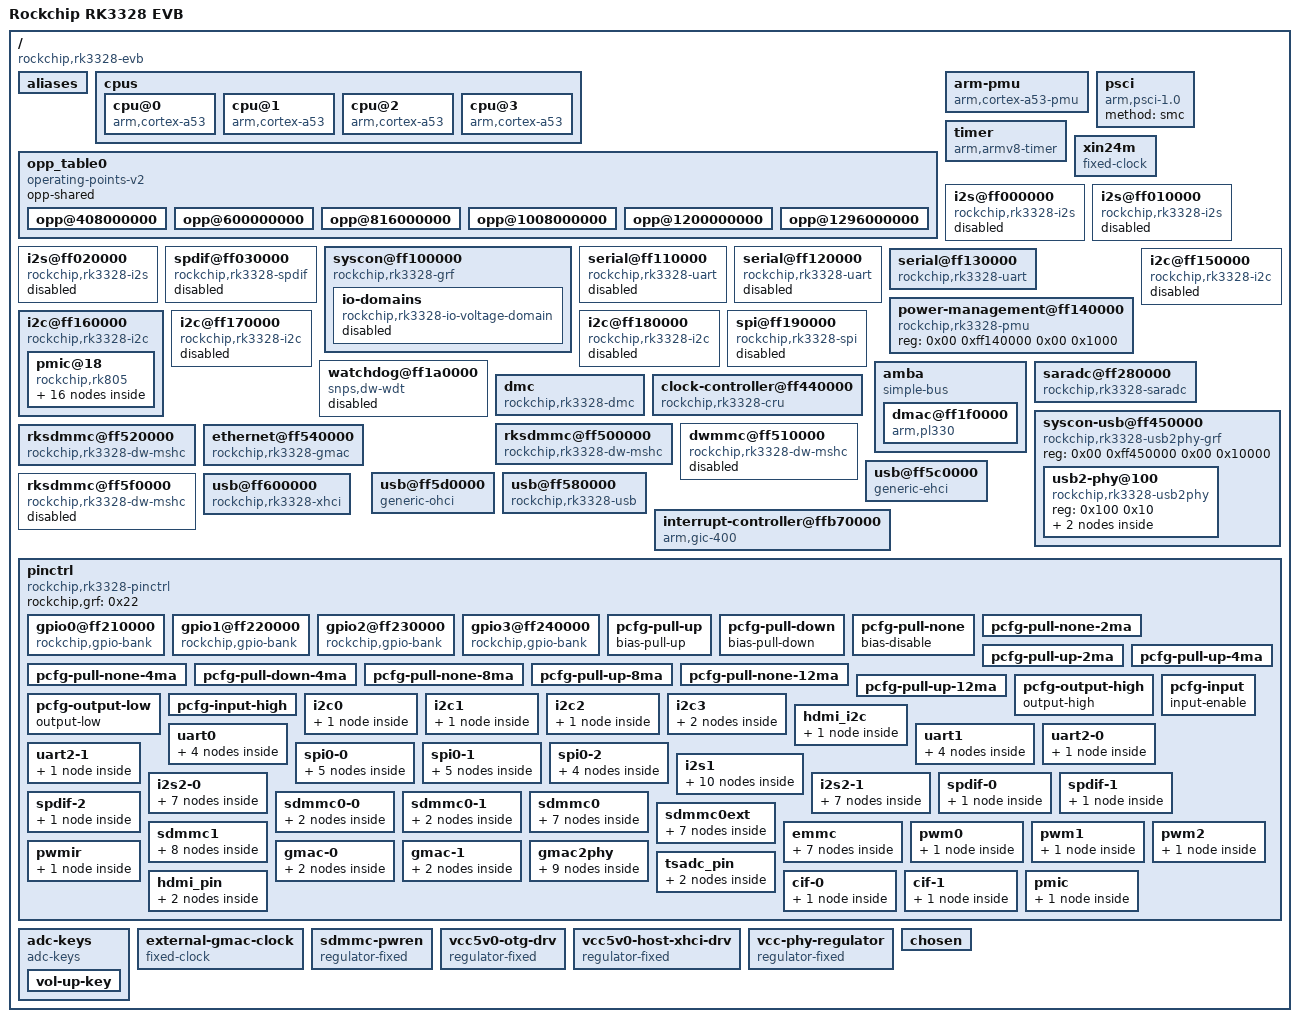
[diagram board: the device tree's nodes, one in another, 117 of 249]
/dts-v1/;

/ {
	compatible = "rockchip,rk3328-evb\0rockchip,rk3328";
	interrupt-parent = <0x01>;
	#address-cells = <0x02>;
	#size-cells = <0x02>;
	model = "Rockchip RK3328 EVB";

	aliases {
		serial0 = "/serial@ff110000";
		serial1 = "/serial@ff120000";
		serial2 = "/serial@ff130000";
		i2c0 = "/i2c@ff150000";
		i2c1 = "/i2c@ff160000";
		i2c2 = "/i2c@ff170000";
		i2c3 = "/i2c@ff180000";
		mmc0 = "/rksdmmc@ff520000";
		mmc1 = "/rksdmmc@ff500000";
		mmc2 = "/rksdmmc@ff5f0000";
	};

	cpus {
		#address-cells = <0x02>;
		#size-cells = <0x00>;

		cpu@0 {
			device_type = "cpu";
			compatible = "arm,cortex-a53\0arm,armv8";
			reg = <0x00 0x00>;
			enable-method = "psci";
			operating-points-v2 = <0x02>;
			phandle = <0x03>;
		};

		cpu@1 {
			device_type = "cpu";
			compatible = "arm,cortex-a53\0arm,armv8";
			reg = <0x00 0x01>;
			enable-method = "psci";
			phandle = <0x04>;
		};

		cpu@2 {
			device_type = "cpu";
			compatible = "arm,cortex-a53\0arm,armv8";
			reg = <0x00 0x02>;
			enable-method = "psci";
			phandle = <0x05>;
		};

		cpu@3 {
			device_type = "cpu";
			compatible = "arm,cortex-a53\0arm,armv8";
			reg = <0x00 0x03>;
			enable-method = "psci";
			phandle = <0x06>;
		};
	};

	opp_table0 {
		compatible = "operating-points-v2";
		opp-shared;
		phandle = <0x02>;

		opp@408000000 {
			opp-hz = <0x00 0x18519600>;
			opp-microvolt = <0xe7ef0>;
			clock-latency-ns = <0x9c40>;
			opp-suspend;
		};

		opp@600000000 {
			opp-hz = <0x00 0x23c34600>;
			opp-microvolt = <0xe7ef0>;
			clock-latency-ns = <0x9c40>;
		};

		opp@816000000 {
			opp-hz = <0x00 0x30a32c00>;
			opp-microvolt = <0xf4240>;
			clock-latency-ns = <0x9c40>;
		};

		opp@1008000000 {
			opp-hz = <0x00 0x3c14dc00>;
			opp-microvolt = <0x10c8e0>;
			clock-latency-ns = <0x9c40>;
		};

		opp@1200000000 {
			opp-hz = <0x00 0x47868c00>;
			opp-microvolt = <0x12b128>;
			clock-latency-ns = <0x9c40>;
		};

		opp@1296000000 {
			opp-hz = <0x00 0x4d3f6400>;
			opp-microvolt = <0x13d620>;
			clock-latency-ns = <0x9c40>;
		};
	};

	arm-pmu {
		compatible = "arm,cortex-a53-pmu";
		interrupts = <0x00 0x64 0x04 0x00 0x65 0x04 0x00 0x66 0x04 0x00 0x67 0x04>;
		interrupt-affinity = <0x03 0x04 0x05 0x06>;
	};

	psci {
		compatible = "arm,psci-1.0";
		method = "smc";
	};

	timer {
		compatible = "arm,armv8-timer";
		interrupts = <0x01 0x0d 0xf08 0x01 0x0e 0xf08 0x01 0x0b 0xf08 0x01 0x0a 0xf08>;
	};

	xin24m {
		compatible = "fixed-clock";
		#clock-cells = <0x00>;
		clock-frequency = <0x16e3600>;
		clock-output-names = "xin24m";
		phandle = <0x23>;
	};

	i2s@ff000000 {
		compatible = "rockchip,rk3328-i2s\0rockchip,rk3066-i2s";
		reg = <0x00 0xff000000 0x00 0x1000>;
		interrupts = <0x00 0x1a 0x04>;
		clocks = <0x07 0x29 0x07 0x137>;
		clock-names = "i2s_clk\0i2s_hclk";
		dmas = <0x08 0x0b 0x08 0x0c>;
		#dma-cells = <0x02>;
		dma-names = "tx\0rx";
		status = "disabled";
	};

	i2s@ff010000 {
		compatible = "rockchip,rk3328-i2s\0rockchip,rk3066-i2s";
		reg = <0x00 0xff010000 0x00 0x1000>;
		interrupts = <0x00 0x1b 0x04>;
		clocks = <0x07 0x2a 0x07 0x138>;
		clock-names = "i2s_clk\0i2s_hclk";
		dmas = <0x08 0x0e 0x08 0x0f>;
		#dma-cells = <0x02>;
		dma-names = "tx\0rx";
		status = "disabled";
	};

	i2s@ff020000 {
		compatible = "rockchip,rk3328-i2s\0rockchip,rk3066-i2s";
		reg = <0x00 0xff020000 0x00 0x1000>;
		interrupts = <0x00 0x1c 0x04>;
		clocks = <0x07 0x2b 0x07 0x139>;
		clock-names = "i2s_clk\0i2s_hclk";
		dmas = <0x08 0x00 0x08 0x01>;
		#dma-cells = <0x02>;
		dma-names = "tx\0rx";
		pinctrl-names = "default\0sleep";
		pinctrl-0 = <0x09 0x0a 0x0b 0x0c 0x0d 0x0e>;
		pinctrl-1 = <0x0f>;
		status = "disabled";
	};

	spdif@ff030000 {
		compatible = "rockchip,rk3328-spdif";
		reg = <0x00 0xff030000 0x00 0x1000>;
		interrupts = <0x00 0x1d 0x04>;
		clocks = <0x07 0x2e 0x07 0x13a>;
		clock-names = "mclk\0hclk";
		dmas = <0x08 0x0a>;
		#dma-cells = <0x01>;
		dma-names = "tx";
		pinctrl-names = "default";
		pinctrl-0 = <0x10>;
		status = "disabled";
	};

	syscon@ff100000 {
		compatible = "rockchip,rk3328-grf\0syscon\0simple-mfd";
		reg = <0x00 0xff100000 0x00 0x1000>;
		#address-cells = <0x01>;
		#size-cells = <0x01>;
		u-boot,dm-pre-reloc;
		phandle = <0x22>;

		io-domains {
			compatible = "rockchip,rk3328-io-voltage-domain";
			status = "disabled";
		};
	};

	serial@ff110000 {
		compatible = "rockchip,rk3328-uart\0snps,dw-apb-uart";
		reg = <0x00 0xff110000 0x00 0x100>;
		interrupts = <0x00 0x37 0x04>;
		clocks = <0x07 0x26 0x07 0xd2>;
		clock-names = "baudclk\0apb_pclk";
		reg-shift = <0x02>;
		reg-io-width = <0x04>;
		dmas = <0x08 0x02 0x08 0x03>;
		#dma-cells = <0x02>;
		pinctrl-names = "default";
		pinctrl-0 = <0x11 0x12 0x13>;
		status = "disabled";
	};

	serial@ff120000 {
		compatible = "rockchip,rk3328-uart\0snps,dw-apb-uart";
		reg = <0x00 0xff120000 0x00 0x100>;
		interrupts = <0x00 0x38 0x04>;
		clocks = <0x07 0x27 0x07 0xd3>;
		clock-names = "sclk_uart\0pclk_uart";
		reg-shift = <0x02>;
		reg-io-width = <0x04>;
		dmas = <0x08 0x04 0x08 0x05>;
		#dma-cells = <0x02>;
		pinctrl-names = "default";
		pinctrl-0 = <0x14 0x15 0x16>;
		status = "disabled";
	};

	serial@ff130000 {
		compatible = "rockchip,rk3328-uart\0snps,dw-apb-uart";
		reg = <0x00 0xff130000 0x00 0x100>;
		interrupts = <0x00 0x39 0x04>;
		clocks = <0x07 0x28 0x07 0xd4>;
		clock-names = "baudclk\0apb_pclk";
		clock-frequency = <0x16e3600>;
		reg-shift = <0x02>;
		reg-io-width = <0x04>;
		dmas = <0x08 0x06 0x08 0x07>;
		#dma-cells = <0x02>;
		pinctrl-names = "default";
		pinctrl-0 = <0x17>;
		status = "okay";
		u-boot,dm-pre-reloc;
	};

	power-management@ff140000 {
		compatible = "rockchip,rk3328-pmu\0syscon\0simple-mfd";
		reg = <0x00 0xff140000 0x00 0x1000>;
	};

	i2c@ff150000 {
		compatible = "rockchip,rk3328-i2c";
		reg = <0x00 0xff150000 0x00 0x1000>;
		interrupts = <0x00 0x24 0x04>;
		#address-cells = <0x01>;
		#size-cells = <0x00>;
		clocks = <0x07 0x37 0x07 0xcd>;
		clock-names = "i2c\0pclk";
		pinctrl-names = "default";
		pinctrl-0 = <0x18>;
		status = "disabled";
	};

	i2c@ff160000 {
		compatible = "rockchip,rk3328-i2c";
		reg = <0x00 0xff160000 0x00 0x1000>;
		interrupts = <0x00 0x25 0x04>;
		#address-cells = <0x01>;
		#size-cells = <0x00>;
		clocks = <0x07 0x38 0x07 0xce>;
		clock-names = "i2c\0pclk";
		pinctrl-names = "default";
		pinctrl-0 = <0x19>;
		status = "okay";
		clock-frequency = <0x61a80>;
		i2c-scl-rising-time-ns = <0xa8>;
		i2c-scl-falling-time-ns = <0x04>;

		pmic@18 {
			compatible = "rockchip,rk805";
			status = "okay";
			reg = <0x18>;
			interrupt-parent = <0x1a>;
			interrupts = <0x06 0x08>;
			pinctrl-names = "default";
			pinctrl-0 = <0x1b>;
			rockchip,system-power-controller;
			wakeup-source;
			gpio-controller;
			#gpio-cells = <0x02>;
			#clock-cells = <0x01>;
			clock-output-names = "xin32k\0rk805-clkout2";

			pwrkey {
				status = "okay";
			};

			regulators {

				DCDC_REG1 {
					regulator-name = "vdd_logic";
					regulator-min-microvolt = <0xadf34>;
					regulator-max-microvolt = <0x162010>;
					regulator-ramp-delay = <0x1771>;
					regulator-boot-on;
					regulator-always-on;

					regulator-state-mem {
						regulator-on-in-suspend;
						regulator-suspend-microvolt = <0xf4240>;
					};
				};

				DCDC_REG2 {
					regulator-name = "vdd_arm";
					regulator-min-microvolt = <0xadf34>;
					regulator-max-microvolt = <0x162010>;
					regulator-ramp-delay = <0x1771>;
					regulator-boot-on;
					regulator-always-on;

					regulator-state-mem {
						regulator-on-in-suspend;
						regulator-suspend-microvolt = <0xf4240>;
					};
				};

				DCDC_REG3 {
					regulator-name = "vcc_ddr";
					regulator-boot-on;
					regulator-always-on;

					regulator-state-mem {
						regulator-on-in-suspend;
					};
				};

				DCDC_REG4 {
					regulator-name = "vcc_io";
					regulator-min-microvolt = <0x325aa0>;
					regulator-max-microvolt = <0x325aa0>;
					regulator-boot-on;
					regulator-always-on;

					regulator-state-mem {
						regulator-on-in-suspend;
						regulator-suspend-microvolt = <0x325aa0>;
					};
				};

				LDO_REG1 {
					regulator-name = "vdd_18";
					regulator-min-microvolt = <0x1b7740>;
					regulator-max-microvolt = <0x1b7740>;
					regulator-boot-on;
					regulator-always-on;

					regulator-state-mem {
						regulator-on-in-suspend;
						regulator-suspend-microvolt = <0x1b7740>;
					};
				};

				LDO_REG2 {
					regulator-name = "vcc_18emmc";
					regulator-min-microvolt = <0x1b7740>;
					regulator-max-microvolt = <0x1b7740>;
					regulator-boot-on;
					regulator-always-on;

					regulator-state-mem {
						regulator-on-in-suspend;
						regulator-suspend-microvolt = <0x1b7740>;
					};
				};

				LDO_REG3 {
					regulator-name = "vdd_10";
					regulator-min-microvolt = <0xf4240>;
					regulator-max-microvolt = <0xf4240>;
					regulator-boot-on;
					regulator-always-on;

					regulator-state-mem {
						regulator-on-in-suspend;
						regulator-suspend-microvolt = <0xf4240>;
					};
				};
			};
		};
	};

	i2c@ff170000 {
		compatible = "rockchip,rk3328-i2c";
		reg = <0x00 0xff170000 0x00 0x1000>;
		interrupts = <0x00 0x26 0x04>;
		#address-cells = <0x01>;
		#size-cells = <0x00>;
		clocks = <0x07 0x39 0x07 0xcf>;
		clock-names = "i2c\0pclk";
		pinctrl-names = "default";
		pinctrl-0 = <0x1c>;
		status = "disabled";
	};

	i2c@ff180000 {
		compatible = "rockchip,rk3328-i2c";
		reg = <0x00 0xff180000 0x00 0x1000>;
		interrupts = <0x00 0x27 0x04>;
		#address-cells = <0x01>;
		#size-cells = <0x00>;
		clocks = <0x07 0x3a 0x07 0xd0>;
		clock-names = "i2c\0pclk";
		pinctrl-names = "default";
		pinctrl-0 = <0x1d>;
		status = "disabled";
	};

	spi@ff190000 {
		compatible = "rockchip,rk3328-spi\0rockchip,rk3066-spi";
		reg = <0x00 0xff190000 0x00 0x1000>;
		interrupts = <0x00 0x31 0x04>;
		#address-cells = <0x01>;
		#size-cells = <0x00>;
		clocks = <0x07 0x20 0x07 0xd1>;
		clock-names = "spiclk\0apb_pclk";
		dmas = <0x08 0x08 0x08 0x09>;
		#dma-cells = <0x02>;
		dma-names = "tx\0rx";
		pinctrl-names = "default";
		pinctrl-0 = <0x1e 0x1f 0x20 0x21>;
		status = "disabled";
	};

	watchdog@ff1a0000 {
		compatible = "snps,dw-wdt";
		reg = <0x00 0xff1a0000 0x00 0x100>;
		interrupts = <0x00 0x28 0x04>;
		status = "disabled";
	};

	amba {
		compatible = "simple-bus";
		#address-cells = <0x02>;
		#size-cells = <0x02>;
		ranges;

		dmac@ff1f0000 {
			compatible = "arm,pl330\0arm,primecell";
			reg = <0x00 0xff1f0000 0x00 0x4000>;
			interrupts = <0x00 0x00 0x04 0x00 0x01 0x04>;
			clocks = <0x07 0x86>;
			clock-names = "apb_pclk";
			#dma-cells = <0x01>;
			phandle = <0x08>;
		};
	};

	saradc@ff280000 {
		compatible = "rockchip,rk3328-saradc\0rockchip,saradc";
		reg = <0x00 0xff280000 0x00 0x100>;
		interrupts = <0x00 0x50 0x04>;
		#io-channel-cells = <0x01>;
		clocks = <0x07 0x25 0x07 0xea>;
		clock-names = "saradc\0apb_pclk";
		resets = <0x07 0x56>;
		reset-names = "saradc-apb";
		status = "okay";
		u-boot,dm-spl;
		phandle = <0x3f>;
	};

	dmc {
		compatible = "rockchip,rk3328-dmc";
		reg = <0x00 0xff400000 0x00 0x1000 0x00 0xff780000 0x00 0x3000 0x00 0xff100000 0x00 0x1000 0x00 0xff440000 0x00 0x1000 0x00 0xff720000 0x00 0x1000 0x00 0xff798000 0x00 0x1000>;
		rockchip,sdram-params = <0x01 0x0c 0x03 0x01 0x00 0x00 0x10 0x10 0x10 0x10 0x00 0x9028b189 0x00 0x21 0x482 0x15 0x222 0xff 0x14d 0x03 0x01 0x00 0x00 0x00 0x43041001 0x64 0x28003b 0xd0 0x20053 0xd4 0x20000 0xd8 0x100 0xdc 0x3200000 0xe0 0x00 0xe4 0x90000 0xf4 0xf011f 0x100 0x7090b06 0x104 0x50209 0x108 0x3030407 0x10c 0x202006 0x110 0x3020204 0x114 0x3030202 0x120 0x903 0x180 0x800020 0x184 0x00 0x190 0x7010001 0x198 0x5001100 0x1a0 0xc0400003 0x240 0x6000604 0x244 0x201 0x250 0xf00 0x490 0x01 0xffffffff 0xffffffff 0xffffffff 0xffffffff 0xffffffff 0xffffffff 0xffffffff 0xffffffff 0xffffffff 0xffffffff 0x04 0x0a 0x28 0x06 0x2c 0x00 0x30 0x05 0xffffffff 0xffffffff 0x77 0x88 0x79 0x79 0x87 0x97 0x87 0x78 0x77 0x78 0x87 0x88 0x87 0x87 0x77 0x78 0x78 0x78 0x78 0x78 0x78 0x78 0x78 0x78 0x69 0x09 0x77 0x78 0x77 0x78 0x77 0x78 0x77 0x78 0x77 0x79 0x09 0x78 0x78 0x78 0x78 0x78 0x78 0x78 0x78 0x78 0x69 0x09 0x77 0x78 0x77 0x77 0x77 0x77 0x77 0x77 0x77 0x79 0x09 0x78 0x78 0x78 0x78 0x78 0x78 0x78 0x78 0x78 0x69 0x09 0x77 0x78 0x77 0x78 0x77 0x78 0x77 0x78 0x77 0x79 0x09 0x78 0x78 0x78 0x78 0x78 0x78 0x78 0x78 0x78 0x69 0x09 0x77 0x78 0x77 0x77 0x77 0x77 0x77 0x77 0x77 0x79 0x09>;
		u-boot,dm-pre-reloc;
	};

	clock-controller@ff440000 {
		compatible = "rockchip,rk3328-cru\0rockchip,cru\0syscon";
		reg = <0x00 0xff440000 0x00 0x1000>;
		rockchip,grf = <0x22>;
		#clock-cells = <0x01>;
		#reset-cells = <0x01>;
		assigned-clocks = <0x07 0x78 0x07 0x3d 0x07 0x1e 0x07 0x26 0x07 0x27 0x07 0x28 0x07 0x88 0x07 0x89 0x07 0x8e 0x07 0x85 0x07 0x83 0x07 0x8a 0x07 0x8c 0x07 0x8d 0x07 0x41 0x07 0x42 0x07 0x44 0x07 0x43 0x07 0x22 0x07 0x5c 0x07 0x35 0x07 0x06 0x07 0x04 0x07 0x03 0x07 0x88 0x07 0x148 0x07 0xd8 0x07 0x89 0x07 0x134 0x07 0xe6 0x07 0x8e 0x07 0x145 0x07 0x85 0x07 0x45 0x07 0x83 0x07 0x8a 0x07 0x8c 0x07 0x8d 0x07 0x41 0x07 0x42 0x07 0x44 0x07 0x43 0x07 0x3e 0x07 0xe5 0x07 0x92 0x07 0xdc 0x07 0x1e 0x07 0x61>;
		assigned-clock-parents = <0x07 0x7a 0x07 0x01 0x07 0x04 0x23 0x23 0x23>;
		assigned-clock-rates = <0x00 0x3a98000 0x00 0x16e3600 0x16e3600 0x16e3600 0x8f0d180 0x8f0d180 0x5f5e100 0x5f5e100 0x5f5e100 0x5f5e100 0x2faf080 0x5f5e100 0x5f5e100 0x5f5e100 0x2faf080 0x2faf080 0x2faf080 0x2faf080 0x16e3600 0x23c34600 0x1d4c0000 0x47868c00 0x8f0d180 0x47868c0 0x47868c0 0x8f0d180 0x47868c0 0x47868c0 0x11e1a300 0x5f5e100 0x11e1a300 0xbebc200 0x17d78400 0x1dcd6500 0xbebc200 0x11e1a300 0x11e1a300 0xee6b280 0xbebc200 0x5f5e100 0x16e3600 0x5f5e100 0x8f0d180 0x2faf080 0x8000 0x8000>;
		u-boot,dm-pre-reloc;
		phandle = <0x07>;
	};

	syscon-usb@ff450000 {
		compatible = "rockchip,rk3328-usb2phy-grf\0simple-mfd\0syscon";
		reg = <0x00 0xff450000 0x00 0x10000>;
		#address-cells = <0x01>;
		#size-cells = <0x01>;
		u-boot,dm-spl;

		usb2-phy@100 {
			compatible = "rockchip,rk3328-usb2phy";
			reg = <0x100 0x10>;
			#phy-cells = <0x01>;
			status = "okay";
			u-boot,dm-spl;

			otg-port {
				#phy-cells = <0x00>;
				interrupts = <0x00 0x3b 0x04 0x00 0x3c 0x04 0x00 0x3d 0x04>;
				interrupt-names = "otg-bvalid\0otg-id\0linestate";
				status = "okay";
				u-boot,dm-spl;
				phandle = <0x32>;
			};

			host-port {
				#phy-cells = <0x00>;
				interrupts = <0x00 0x3e 0x04>;
				interrupt-names = "linestate";
				status = "okay";
				u-boot,dm-spl;
				phandle = <0x30>;
			};
		};
	};

	rksdmmc@ff500000 {
		compatible = "rockchip,rk3328-dw-mshc\0rockchip,rk3288-dw-mshc";
		reg = <0x00 0xff500000 0x00 0x4000>;
		max-frequency = <0x8f0d180>;
		clocks = <0x07 0x13d 0x07 0x21 0x07 0x4a 0x07 0x4e>;
		clock-names = "biu\0ciu\0ciu-drv\0ciu-sample";
		fifo-depth = <0x100>;
		interrupts = <0x00 0x0c 0x04>;
		status = "okay";
		bus-width = <0x04>;
		cap-mmc-highspeed;
		cap-sd-highspeed;
		card-detect-delay = <0xc8>;
		disable-wp;
		num-slots = <0x01>;
		pinctrl-names = "default";
		pinctrl-0 = <0x24 0x25 0x26 0x27>;
		vmmc-supply = <0x28>;
		u-boot,dm-spl;
	};

	dwmmc@ff510000 {
		compatible = "rockchip,rk3328-dw-mshc\0rockchip,rk3288-dw-mshc";
		reg = <0x00 0xff510000 0x00 0x4000>;
		max-frequency = <0x8f0d180>;
		clocks = <0x07 0x13e 0x07 0x22 0x07 0x4b 0x07 0x4f>;
		clock-names = "biu\0ciu\0ciu-drv\0ciu-sample";
		fifo-depth = <0x100>;
		interrupts = <0x00 0x0d 0x04>;
		status = "disabled";
	};

	rksdmmc@ff520000 {
		compatible = "rockchip,rk3328-dw-mshc\0rockchip,rk3288-dw-mshc";
		reg = <0x00 0xff520000 0x00 0x4000>;
		max-frequency = <0x8f0d180>;
		clocks = <0x07 0x13f 0x07 0x23 0x07 0x4c 0x07 0x50>;
		clock-names = "biu\0ciu\0ciu-drv\0ciu-sample";
		fifo-depth = <0x100>;
		interrupts = <0x00 0x0e 0x04>;
		status = "okay";
		bus-width = <0x08>;
		cap-mmc-highspeed;
		supports-emmc;
		disable-wp;
		non-removable;
		num-slots = <0x01>;
		pinctrl-names = "default";
		pinctrl-0 = <0x29 0x2a 0x2b>;
		u-boot,dm-spl;
	};

	ethernet@ff540000 {
		compatible = "rockchip,rk3328-gmac";
		reg = <0x00 0xff540000 0x00 0x10000>;
		rockchip,grf = <0x22>;
		interrupts = <0x00 0x18 0x04>;
		interrupt-names = "macirq";
		clocks = <0x07 0x64 0x07 0x57 0x07 0x58 0x07 0x5a 0x07 0x59 0x07 0x96 0x07 0xdf>;
		clock-names = "stmmaceth\0mac_clk_rx\0mac_clk_tx\0clk_mac_ref\0clk_mac_refout\0aclk_mac\0pclk_mac";
		resets = <0x07 0x63>;
		reset-names = "stmmaceth";
		status = "okay";
		phy-supply = <0x2c>;
		phy-mode = "rgmii";
		clock_in_out = "input";
		snps,reset-gpio = <0x2d 0x12 0x01>;
		snps,reset-active-low;
		snps,reset-delays-us = <0x00 0x2710 0xc350>;
		assigned-clocks = <0x07 0x64 0x07 0x66>;
		assigned-clock-parents = <0x2e 0x2e>;
		pinctrl-names = "default";
		pinctrl-0 = <0x2f>;
		tx_delay = <0x26>;
		rx_delay = <0x11>;
	};

	usb@ff5c0000 {
		compatible = "generic-ehci";
		reg = <0x00 0xff5c0000 0x00 0x10000>;
		interrupts = <0x00 0x10 0x04>;
		phys = <0x30>;
		phy-names = "usb";
		status = "okay";
		vbus-supply = <0x31>;
		u-boot,dm-spl;
	};

	usb@ff5d0000 {
		compatible = "generic-ohci";
		reg = <0x00 0xff5d0000 0x00 0x10000>;
		interrupts = <0x00 0x11 0x04>;
		phys = <0x30>;
		phy-names = "usb";
		status = "okay";
	};

	usb@ff580000 {
		compatible = "rockchip,rk3328-usb\0rockchip,rk3066-usb\0snps,dwc2";
		reg = <0x00 0xff580000 0x00 0x40000>;
		interrupts = <0x00 0x17 0x04>;
		hnp-srp-disable;
		dr_mode = "otg";
		phys = <0x32>;
		phy-names = "usb";
		status = "okay";
		vbus-supply = <0x31>;
		u-boot,dm-spl;
	};

	rksdmmc@ff5f0000 {
		compatible = "rockchip,rk3328-dw-mshc\0rockchip,rk3288-dw-mshc";
		reg = <0x00 0xff5f0000 0x00 0x4000>;
		max-frequency = <0x8f0d180>;
		clocks = <0x07 0x13d 0x07 0x21>;
		clock-names = "biu\0ciu";
		fifo-depth = <0x100>;
		interrupts = <0x00 0x04 0x04>;
		status = "disabled";
	};

	usb@ff600000 {
		compatible = "rockchip,rk3328-xhci";
		reg = <0x00 0xff600000 0x00 0x100000>;
		interrupts = <0x00 0x43 0x04>;
		snps,dis-enblslpm-quirk;
		snps,phyif-utmi-bits = <0x10>;
		snps,dis-u2-freeclk-exists-quirk;
		snps,dis-u2-susphy-quirk;
		status = "okay";
		vbus-supply = <0x33>;
		u-boot,dm-spl;
	};

	interrupt-controller@ffb70000 {
		compatible = "arm,gic-400";
		#interrupt-cells = <0x03>;
		#address-cells = <0x00>;
		interrupt-controller;
		reg = <0x00 0xff811000 0x00 0x1000 0x00 0xff812000 0x00 0x2000 0x00 0xff814000 0x00 0x2000 0x00 0xff816000 0x00 0x2000>;
		interrupts = <0x01 0x09 0xf04>;
		phandle = <0x01>;
	};

	pinctrl {
		compatible = "rockchip,rk3328-pinctrl";
		rockchip,grf = <0x22>;
		#address-cells = <0x02>;
		#size-cells = <0x02>;
		ranges;
		u-boot,dm-spl;

		gpio0@ff210000 {
			compatible = "rockchip,gpio-bank";
			reg = <0x00 0xff210000 0x00 0x100>;
			interrupts = <0x00 0x33 0x04>;
			clocks = <0x07 0xc8>;
			gpio-controller;
			#gpio-cells = <0x02>;
			interrupt-controller;
			#interrupt-cells = <0x02>;
			phandle = <0x40>;
		};

		gpio1@ff220000 {
			compatible = "rockchip,gpio-bank";
			reg = <0x00 0xff220000 0x00 0x100>;
			interrupts = <0x00 0x34 0x04>;
			clocks = <0x07 0xc9>;
			gpio-controller;
			#gpio-cells = <0x02>;
			interrupt-controller;
			#interrupt-cells = <0x02>;
			phandle = <0x2d>;
		};

		gpio2@ff230000 {
			compatible = "rockchip,gpio-bank";
			reg = <0x00 0xff230000 0x00 0x100>;
			interrupts = <0x00 0x35 0x04>;
			clocks = <0x07 0xca>;
			gpio-controller;
			#gpio-cells = <0x02>;
			interrupt-controller;
			#interrupt-cells = <0x02>;
			phandle = <0x1a>;
		};

		gpio3@ff240000 {
			compatible = "rockchip,gpio-bank";
			reg = <0x00 0xff240000 0x00 0x100>;
			interrupts = <0x00 0x36 0x04>;
			clocks = <0x07 0xcb>;
			gpio-controller;
			#gpio-cells = <0x02>;
			interrupt-controller;
			#interrupt-cells = <0x02>;
		};

		pcfg-pull-up {
			bias-pull-up;
			phandle = <0x35>;
		};

		pcfg-pull-down {
			bias-pull-down;
			phandle = <0x3e>;
		};

		pcfg-pull-none {
			bias-disable;
			phandle = <0x34>;
		};

		pcfg-pull-none-2ma {
			bias-disable;
			drive-strength = <0x02>;
			phandle = <0x3d>;
		};

		pcfg-pull-up-2ma {
			bias-pull-up;
			drive-strength = <0x02>;
		};

		pcfg-pull-up-4ma {
			bias-pull-up;
			drive-strength = <0x04>;
			phandle = <0x37>;
		};

		pcfg-pull-none-4ma {
			bias-disable;
			drive-strength = <0x04>;
			phandle = <0x38>;
		};

		pcfg-pull-down-4ma {
			bias-pull-down;
			drive-strength = <0x04>;
		};

		pcfg-pull-none-8ma {
			bias-disable;
			drive-strength = <0x08>;
			phandle = <0x39>;
		};

		pcfg-pull-up-8ma {
			bias-pull-up;
			drive-strength = <0x08>;
			phandle = <0x3a>;
		};

		pcfg-pull-none-12ma {
			bias-disable;
			drive-strength = <0x0c>;
			phandle = <0x3b>;
		};

		pcfg-pull-up-12ma {
			bias-pull-up;
			drive-strength = <0x0c>;
			phandle = <0x3c>;
		};

		pcfg-output-high {
			output-high;
		};

		pcfg-output-low {
			output-low;
		};

		pcfg-input-high {
			bias-pull-up;
			input-enable;
			phandle = <0x36>;
		};

		pcfg-input {
			input-enable;
		};

		i2c0 {

			i2c0-xfer {
				rockchip,pins = <0x02 0x18 0x01 0x34 0x02 0x19 0x01 0x34>;
				phandle = <0x18>;
			};
		};

		i2c1 {

			i2c1-xfer {
				rockchip,pins = <0x02 0x04 0x02 0x34 0x02 0x05 0x02 0x34>;
				phandle = <0x19>;
			};
		};

		i2c2 {

			i2c2-xfer {
				rockchip,pins = <0x02 0x0d 0x01 0x34 0x02 0x0e 0x01 0x34>;
				phandle = <0x1c>;
			};
		};

		i2c3 {

			i2c3-xfer {
				rockchip,pins = <0x00 0x05 0x02 0x34 0x00 0x06 0x02 0x34>;
				phandle = <0x1d>;
			};

			i2c3-gpio {
				rockchip,pins = <0x00 0x05 0x00 0x34 0x00 0x06 0x00 0x34>;
			};
		};

		hdmi_i2c {

			hdmii2c-xfer {
				rockchip,pins = <0x00 0x05 0x01 0x34 0x00 0x06 0x01 0x34>;
			};
		};

		uart0 {

			uart0-xfer {
				rockchip,pins = <0x01 0x09 0x01 0x35 0x01 0x08 0x01 0x35>;
				phandle = <0x11>;
			};

			uart0-cts {
				rockchip,pins = <0x01 0x0b 0x01 0x34>;
				phandle = <0x12>;
			};

			uart0-rts {
				rockchip,pins = <0x01 0x0a 0x01 0x34>;
				phandle = <0x13>;
			};

			uart0-rts-gpio {
				rockchip,pins = <0x01 0x0a 0x00 0x34>;
			};
		};

		uart1 {

			uart1-xfer {
				rockchip,pins = <0x03 0x04 0x04 0x35 0x03 0x06 0x04 0x35>;
				phandle = <0x14>;
			};

			uart1-cts {
				rockchip,pins = <0x03 0x07 0x04 0x34>;
				phandle = <0x15>;
			};

			uart1-rts {
				rockchip,pins = <0x03 0x05 0x04 0x34>;
				phandle = <0x16>;
			};

			uart1-rts-gpio {
				rockchip,pins = <0x03 0x05 0x00 0x34>;
			};
		};

		uart2-0 {

			uart2m0-xfer {
				rockchip,pins = <0x01 0x00 0x02 0x35 0x01 0x01 0x02 0x35>;
			};
		};

		uart2-1 {

			uart2m1-xfer {
				rockchip,pins = <0x02 0x00 0x01 0x35 0x02 0x01 0x01 0x35>;
				phandle = <0x17>;
			};
		};

		spi0-0 {

			spi0m0-clk {
				rockchip,pins = <0x02 0x08 0x01 0x35>;
			};

			spi0m0-cs0 {
				rockchip,pins = <0x02 0x0b 0x01 0x35>;
			};

			spi0m0-tx {
				rockchip,pins = <0x02 0x09 0x01 0x35>;
			};

			spi0m0-rx {
				rockchip,pins = <0x02 0x0a 0x01 0x35>;
			};

			spi0m0-cs1 {
				rockchip,pins = <0x02 0x0c 0x01 0x35>;
			};
		};

		spi0-1 {

			spi0m1-clk {
				rockchip,pins = <0x03 0x17 0x02 0x35>;
			};

			spi0m1-cs0 {
				rockchip,pins = <0x03 0x1a 0x02 0x35>;
			};

			spi0m1-tx {
				rockchip,pins = <0x03 0x19 0x02 0x35>;
			};

			spi0m1-rx {
				rockchip,pins = <0x03 0x18 0x02 0x35>;
			};

			spi0m1-cs1 {
				rockchip,pins = <0x03 0x1b 0x02 0x35>;
			};
		};

		spi0-2 {

			spi0m2-clk {
				rockchip,pins = <0x03 0x00 0x04 0x35>;
				phandle = <0x1e>;
			};

			spi0m2-cs0 {
				rockchip,pins = <0x03 0x08 0x03 0x35>;
				phandle = <0x21>;
			};

			spi0m2-tx {
				rockchip,pins = <0x03 0x01 0x04 0x35>;
				phandle = <0x1f>;
			};

			spi0m2-rx {
				rockchip,pins = <0x03 0x02 0x04 0x35>;
				phandle = <0x20>;
			};
		};

		i2s1 {

			i2s1-mclk {
				rockchip,pins = <0x02 0x0f 0x01 0x34>;
			};

			i2s1-sclk {
				rockchip,pins = <0x02 0x12 0x01 0x34>;
			};

			i2s1-lrckrx {
				rockchip,pins = <0x02 0x10 0x01 0x34>;
			};

			i2s1-lrcktx {
				rockchip,pins = <0x02 0x11 0x01 0x34>;
			};

			i2s1-sdi {
				rockchip,pins = <0x02 0x13 0x01 0x34>;
			};

			i2s1-sdo {
				rockchip,pins = <0x02 0x17 0x01 0x34>;
			};

			i2s1-sdio1 {
				rockchip,pins = <0x02 0x14 0x01 0x34>;
			};

			i2s1-sdio2 {
				rockchip,pins = <0x02 0x15 0x01 0x34>;
			};

			i2s1-sdio3 {
				rockchip,pins = <0x02 0x16 0x01 0x34>;
			};

			i2s1-sleep {
				rockchip,pins = <0x02 0x0f 0x00 0x36 0x02 0x10 0x00 0x36 0x02 0x11 0x00 0x36 0x02 0x12 0x00 0x36 0x02 0x13 0x00 0x36 0x02 0x14 0x00 0x36 0x02 0x15 0x00 0x36 0x02 0x16 0x00 0x36 0x02 0x17 0x00 0x36>;
			};
		};

		i2s2-0 {

			i2s2m0-mclk {
				rockchip,pins = <0x01 0x15 0x01 0x34>;
				phandle = <0x09>;
			};

			i2s2m0-sclk {
				rockchip,pins = <0x01 0x16 0x01 0x34>;
				phandle = <0x0a>;
			};

			i2s2m0-lrckrx {
				rockchip,pins = <0x01 0x1a 0x01 0x34>;
				phandle = <0x0c>;
			};

			i2s2m0-lrcktx {
				rockchip,pins = <0x01 0x17 0x01 0x34>;
				phandle = <0x0b>;
			};

			i2s2m0-sdi {
				rockchip,pins = <0x01 0x18 0x01 0x34>;
				phandle = <0x0e>;
			};

			i2s2m0-sdo {
				rockchip,pins = <0x01 0x19 0x01 0x34>;
				phandle = <0x0d>;
			};

			i2s2m0-sleep {
				rockchip,pins = <0x01 0x15 0x00 0x36 0x01 0x16 0x00 0x36 0x01 0x1a 0x00 0x36 0x01 0x17 0x00 0x36 0x01 0x18 0x00 0x36 0x01 0x19 0x00 0x36>;
				phandle = <0x0f>;
			};
		};

		i2s2-1 {

			i2s2m1-mclk {
				rockchip,pins = <0x01 0x15 0x01 0x34>;
			};

			i2s2m1-sclk {
				rockchip,pins = <0x03 0x00 0x06 0x34>;
			};

			i2sm1-lrckrx {
				rockchip,pins = <0x03 0x08 0x06 0x34>;
			};

			i2s2m1-lrcktx {
				rockchip,pins = <0x03 0x08 0x04 0x34>;
			};

			i2s2m1-sdi {
				rockchip,pins = <0x03 0x02 0x06 0x34>;
			};

			i2s2m1-sdo {
				rockchip,pins = <0x03 0x01 0x06 0x34>;
			};

			i2s2m1-sleep {
				rockchip,pins = <0x01 0x15 0x00 0x36 0x03 0x00 0x00 0x36 0x03 0x08 0x00 0x36 0x03 0x02 0x00 0x36 0x03 0x01 0x00 0x36>;
			};
		};

		spdif-0 {

			spdifm0-tx {
				rockchip,pins = <0x00 0x1b 0x01 0x34>;
			};
		};

		spdif-1 {

			spdifm1-tx {
				rockchip,pins = <0x02 0x11 0x02 0x34>;
			};
		};

		spdif-2 {

			spdifm2-tx {
				rockchip,pins = <0x00 0x02 0x02 0x34>;
				phandle = <0x10>;
			};
		};

		sdmmc0-0 {

			sdmmc0m0-pwren {
				rockchip,pins = <0x02 0x07 0x01 0x37>;
			};

			sdmmc0m0-gpio {
				rockchip,pins = <0x02 0x07 0x00 0x37>;
			};
		};

		sdmmc0-1 {

			sdmmc0m1-pwren {
				rockchip,pins = <0x00 0x1e 0x03 0x37>;
			};

			sdmmc0m1-gpio {
				rockchip,pins = <0x00 0x1e 0x00 0x37>;
			};
		};

		sdmmc0 {

			sdmmc0-clk {
				rockchip,pins = <0x01 0x06 0x01 0x38>;
				u-boot,dm-spl;
				phandle = <0x24>;
			};

			sdmmc0-cmd {
				rockchip,pins = <0x01 0x04 0x01 0x37>;
				u-boot,dm-spl;
				phandle = <0x25>;
			};

			sdmmc0-dectn {
				rockchip,pins = <0x01 0x05 0x01 0x37>;
				u-boot,dm-spl;
				phandle = <0x26>;
			};

			sdmmc0-wrprt {
				rockchip,pins = <0x01 0x07 0x01 0x37>;
			};

			sdmmc0-bus1 {
				rockchip,pins = <0x01 0x00 0x01 0x37>;
			};

			sdmmc0-bus4 {
				rockchip,pins = <0x01 0x00 0x01 0x37 0x01 0x01 0x01 0x37 0x01 0x02 0x01 0x37 0x01 0x03 0x01 0x37>;
				u-boot,dm-spl;
				phandle = <0x27>;
			};

			sdmmc0-gpio {
				rockchip,pins = <0x01 0x06 0x00 0x37 0x01 0x04 0x00 0x37 0x01 0x05 0x00 0x37 0x01 0x07 0x00 0x37 0x01 0x03 0x00 0x37 0x01 0x02 0x00 0x37 0x01 0x01 0x00 0x37 0x01 0x00 0x00 0x37>;
			};
		};

		sdmmc0ext {

			sdmmc0ext-clk {
				rockchip,pins = <0x03 0x02 0x03 0x38>;
			};

			sdmmc0ext-cmd {
				rockchip,pins = <0x03 0x00 0x03 0x37>;
			};

			sdmmc0ext-wrprt {
				rockchip,pins = <0x03 0x03 0x03 0x37>;
			};

			sdmmc0ext-dectn {
				rockchip,pins = <0x03 0x01 0x03 0x37>;
			};

			sdmmc0ext-bus1 {
				rockchip,pins = <0x03 0x04 0x03 0x37>;
			};

			sdmmc0ext-bus4 {
				rockchip,pins = <0x03 0x04 0x03 0x37 0x03 0x05 0x03 0x37 0x03 0x06 0x03 0x37 0x03 0x07 0x03 0x37>;
			};

			sdmmc0ext-gpio {
				rockchip,pins = <0x03 0x00 0x00 0x37 0x03 0x01 0x00 0x37 0x03 0x02 0x00 0x37 0x03 0x03 0x00 0x37 0x03 0x04 0x00 0x37 0x03 0x05 0x00 0x37 0x03 0x06 0x00 0x37 0x03 0x07 0x00 0x37>;
			};
		};

		sdmmc1 {

			sdmmc1-clk {
				rockchip,pins = <0x01 0x0c 0x01 0x39>;
			};

			sdmmc1-cmd {
				rockchip,pins = <0x01 0x0d 0x01 0x3a>;
			};

			sdmmc1-pwren {
				rockchip,pins = <0x01 0x12 0x01 0x3a>;
			};

			sdmmc1-wrprt {
				rockchip,pins = <0x01 0x14 0x01 0x3a>;
			};

			sdmmc1-dectn {
				rockchip,pins = <0x01 0x13 0x01 0x3a>;
			};

			sdmmc1-bus1 {
				rockchip,pins = <0x01 0x0e 0x01 0x3a>;
			};

			sdmmc1-bus4 {
				rockchip,pins = <0x01 0x0c 0x01 0x3a 0x01 0x0d 0x01 0x3a 0x01 0x10 0x01 0x3a 0x01 0x11 0x01 0x3a>;
			};

			sdmmc1-gpio {
				rockchip,pins = <0x01 0x0c 0x00 0x37 0x01 0x0d 0x00 0x37 0x01 0x0e 0x00 0x37 0x01 0x0f 0x00 0x37 0x01 0x10 0x00 0x37 0x01 0x11 0x00 0x37 0x01 0x12 0x00 0x37 0x01 0x13 0x00 0x37 0x01 0x14 0x00 0x37>;
			};
		};

		emmc {

			emmc-clk {
				rockchip,pins = <0x03 0x15 0x02 0x3b>;
				phandle = <0x29>;
			};

			emmc-cmd {
				rockchip,pins = <0x03 0x13 0x02 0x3c>;
				phandle = <0x2a>;
			};

			emmc-pwren {
				rockchip,pins = <0x03 0x16 0x02 0x34>;
			};

			emmc-rstnout {
				rockchip,pins = <0x03 0x14 0x02 0x34>;
			};

			emmc-bus1 {
				rockchip,pins = <0x00 0x07 0x02 0x3c>;
			};

			emmc-bus4 {
				rockchip,pins = <0x00 0x07 0x02 0x3c 0x02 0x1c 0x02 0x3c 0x02 0x1d 0x02 0x3c 0x02 0x1e 0x02 0x3c>;
			};

			emmc-bus8 {
				rockchip,pins = <0x00 0x07 0x02 0x3c 0x02 0x1c 0x02 0x3c 0x02 0x1d 0x02 0x3c 0x02 0x1e 0x02 0x3c 0x02 0x1f 0x02 0x3c 0x03 0x10 0x02 0x3c 0x03 0x11 0x02 0x3c 0x03 0x12 0x02 0x3c>;
				phandle = <0x2b>;
			};
		};

		pwm0 {

			pwm0-pin {
				rockchip,pins = <0x02 0x04 0x01 0x34>;
			};
		};

		pwm1 {

			pwm1-pin {
				rockchip,pins = <0x02 0x05 0x01 0x34>;
			};
		};

		pwm2 {

			pwm2-pin {
				rockchip,pins = <0x02 0x06 0x01 0x34>;
			};
		};

		pwmir {

			pwmir-pin {
				rockchip,pins = <0x02 0x02 0x01 0x34>;
			};
		};

		gmac-0 {

			rgmiim0-pins {
				rockchip,pins = <0x00 0x08 0x01 0x3b 0x00 0x0a 0x01 0x34 0x00 0x0b 0x01 0x34 0x00 0x0c 0x01 0x3b 0x00 0x18 0x01 0x34 0x00 0x19 0x01 0x34 0x00 0x13 0x01 0x34 0x00 0x0e 0x01 0x34 0x00 0x0f 0x01 0x34 0x00 0x10 0x01 0x3b 0x00 0x11 0x01 0x3b 0x00 0x14 0x01 0x34 0x00 0x15 0x01 0x34 0x00 0x17 0x01 0x3b 0x00 0x16 0x01 0x3b>;
			};

			rmiim0-pins {
				rockchip,pins = <0x00 0x0b 0x01 0x34 0x00 0x0c 0x01 0x3b 0x00 0x18 0x01 0x34 0x00 0x0d 0x01 0x34 0x00 0x19 0x01 0x34 0x00 0x13 0x01 0x34 0x00 0x0e 0x01 0x34 0x00 0x0f 0x01 0x34 0x00 0x10 0x01 0x3b 0x00 0x11 0x01 0x3b>;
			};
		};

		gmac-1 {

			rgmiim1-pins {
				rockchip,pins = <0x01 0x0c 0x02 0x3b 0x01 0x0d 0x02 0x3d 0x01 0x13 0x02 0x3d 0x01 0x19 0x02 0x3b 0x01 0x15 0x02 0x3d 0x01 0x16 0x02 0x3d 0x01 0x17 0x02 0x3d 0x01 0x0a 0x02 0x3d 0x01 0x0b 0x02 0x3d 0x01 0x08 0x02 0x3b 0x01 0x09 0x02 0x3b 0x01 0x0e 0x02 0x3d 0x01 0x0f 0x02 0x3d 0x01 0x10 0x02 0x3b 0x01 0x11 0x02 0x3b 0x00 0x08 0x01 0x34 0x00 0x0c 0x01 0x34 0x00 0x18 0x01 0x34 0x00 0x10 0x01 0x34 0x00 0x11 0x01 0x34 0x00 0x17 0x01 0x34 0x00 0x16 0x01 0x34>;
				phandle = <0x2f>;
			};

			rmiim1-pins {
				rockchip,pins = <0x01 0x13 0x02 0x3d 0x01 0x19 0x02 0x3b 0x01 0x15 0x02 0x3d 0x01 0x18 0x02 0x3d 0x01 0x16 0x02 0x3d 0x01 0x17 0x02 0x3d 0x01 0x0a 0x02 0x3d 0x01 0x0b 0x02 0x3d 0x01 0x08 0x02 0x3b 0x01 0x09 0x02 0x3b 0x00 0x0b 0x01 0x34 0x00 0x0c 0x01 0x34 0x00 0x18 0x01 0x34 0x00 0x13 0x01 0x34 0x00 0x10 0x01 0x34 0x00 0x11 0x01 0x34>;
			};
		};

		gmac2phy {

			fephyled-speed100 {
				rockchip,pins = <0x00 0x1f 0x01 0x34>;
			};

			fephyled-speed10 {
				rockchip,pins = <0x00 0x1e 0x01 0x34>;
			};

			fephyled-duplex {
				rockchip,pins = <0x00 0x1e 0x02 0x34>;
			};

			fephyled-rxm0 {
				rockchip,pins = <0x00 0x1d 0x01 0x34>;
			};

			fephyled-txm0 {
				rockchip,pins = <0x00 0x1d 0x02 0x34>;
			};

			fephyled-linkm0 {
				rockchip,pins = <0x00 0x1c 0x01 0x34>;
			};

			fephyled-rxm1 {
				rockchip,pins = <0x02 0x19 0x02 0x34>;
			};

			fephyled-txm1 {
				rockchip,pins = <0x02 0x19 0x03 0x34>;
			};

			fephyled-linkm1 {
				rockchip,pins = <0x02 0x18 0x02 0x34>;
			};
		};

		tsadc_pin {

			tsadc-int {
				rockchip,pins = <0x02 0x0d 0x02 0x34>;
			};

			tsadc-gpio {
				rockchip,pins = <0x02 0x0d 0x00 0x34>;
			};
		};

		hdmi_pin {

			hdmi-cec {
				rockchip,pins = <0x00 0x03 0x01 0x34>;
			};

			hdmi-hpd {
				rockchip,pins = <0x00 0x04 0x01 0x3e>;
			};
		};

		cif-0 {

			dvp-d2d9-m0 {
				rockchip,pins = <0x03 0x04 0x02 0x34 0x03 0x05 0x02 0x34 0x03 0x06 0x02 0x34 0x03 0x07 0x02 0x34 0x03 0x08 0x02 0x34 0x03 0x09 0x02 0x34 0x03 0x0a 0x02 0x34 0x03 0x0b 0x02 0x34 0x03 0x01 0x02 0x34 0x03 0x00 0x02 0x34 0x03 0x03 0x02 0x34 0x03 0x02 0x02 0x34>;
			};
		};

		cif-1 {

			dvp-d2d9-m1 {
				rockchip,pins = <0x03 0x04 0x02 0x34 0x03 0x05 0x02 0x34 0x03 0x06 0x02 0x34 0x03 0x07 0x02 0x34 0x03 0x08 0x02 0x34 0x02 0x10 0x04 0x34 0x02 0x11 0x04 0x34 0x02 0x12 0x04 0x34 0x03 0x01 0x02 0x34 0x03 0x00 0x02 0x34 0x02 0x0f 0x04 0x34 0x03 0x02 0x02 0x34>;
			};
		};

		pmic {

			pmic-int-l {
				rockchip,pins = <0x02 0x06 0x00 0x35>;
				phandle = <0x1b>;
			};
		};
	};

	adc-keys {
		status = "okay";
		u-boot,dm-pre-reloc;
		compatible = "adc-keys";
		io-channels = <0x3f 0x00>;
		io-channel-names = "buttons";
		keyup-threshold-microvolt = <0x1b7740>;

		vol-up-key {
			u-boot,dm-pre-reloc;
			linux,code = <0x73>;
			label = "volume up";
			press-threshold-microvolt = <0x2710>;
		};
	};

	external-gmac-clock {
		compatible = "fixed-clock";
		clock-frequency = <0x7735940>;
		clock-output-names = "gmac_clkin";
		#clock-cells = <0x00>;
		phandle = <0x2e>;
	};

	sdmmc-pwren {
		compatible = "regulator-fixed";
		regulator-name = "vcc3v3";
		gpio = <0x40 0x1e 0x01>;
		regulator-always-on;
		regulator-boot-on;
		u-boot,dm-spl;
		phandle = <0x28>;
	};

	vcc5v0-otg-drv {
		compatible = "regulator-fixed";
		enable-active-high;
		regulator-name = "vcc5v0_otg";
		gpio = <0x40 0x1b 0x00>;
		regulator-min-microvolt = <0x4c4b40>;
		regulator-max-microvolt = <0x4c4b40>;
		u-boot,dm-spl;
		phandle = <0x31>;
	};

	vcc5v0-host-xhci-drv {
		compatible = "regulator-fixed";
		enable-active-high;
		regulator-name = "vcc5v0_host_xhci";
		gpio = <0x40 0x00 0x00>;
		regulator-min-microvolt = <0x4c4b40>;
		regulator-max-microvolt = <0x4c4b40>;
		u-boot,dm-spl;
		phandle = <0x33>;
	};

	vcc-phy-regulator {
		compatible = "regulator-fixed";
		regulator-name = "vcc_phy";
		regulator-always-on;
		regulator-boot-on;
		phandle = <0x2c>;
	};

	chosen {
		u-boot,spl-boot-order = "/rksdmmc@ff500000\0/rksdmmc@ff520000";
		stdout-path = "/serial@ff130000";
	};
};
